VERSION ""

NS_ :

BS_:
BU_: Driving Always Acceories Battery A/C
BO_ 465 First: 8 Driving
   SG_ Accelerator_Position : 47|8@0+ (0.393701,0) [0|100] "%" Driving
   SG_ Brake_Switch : 55|8@0+ (1,0) [0|100] "" Driving

BO_ 674 Power: 8 Always
   SG_ Power_Consumption : 55|16@0+ (0.0004,0) [0|1] "KW" Always
   SG_ Drive_Mode : 31|8@0+ (1,0) [0|1] "" Driving

BO_ 648 Acceories: 8 Acceories
   SG_ Doors : 23|8@0+ (1,0) [0|1] "" Acceories
   SG_ Lights : 15|8@0+ (1,0) [0|1] "" Acceories

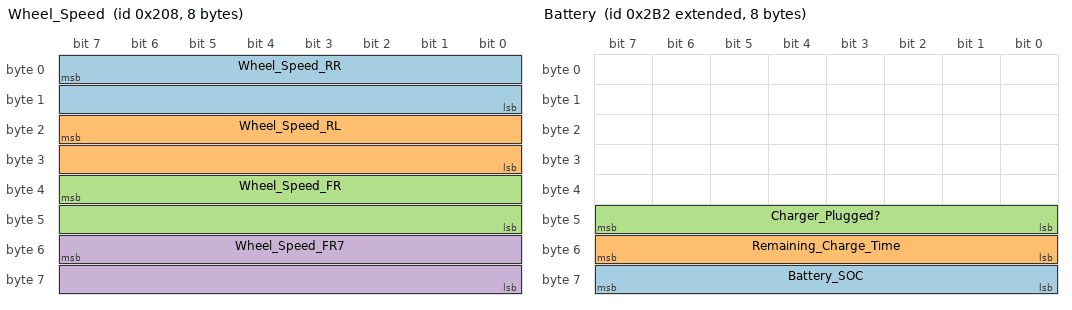
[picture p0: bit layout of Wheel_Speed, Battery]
BO_ 520 Wheel_Speed: 8 Driving
   SG_ Wheel_Speed_RR : 7|16@0+ (0.06,0) [0|1] "Km/h" Driving
   SG_ Wheel_Speed_RL : 23|16@0+ (0.06,0) [0|1] "Km/h" Driving
   SG_ Wheel_Speed_FR : 39|16@0+ (0.06,0) [0|1] "Km/h" Vector__XXX
   SG_ Wheel_Speed_FR7 : 55|16@0+ (0.06,0) [0|1] "Km/h" Driving

BO_ 804 Coolant: 8 Driving
   SG_ Coolant_Temp : 15|8@0+ (0.5556,-17.7778) [0|1] "C°" Vector__XXX

BO_ 616 Gear_Position: 8 Driving
   SG_ Gear_Position : 15|16@0+ (1,0) [0|1] "" Driving

BO_ 658 Drive_Mode: 8 Driving
   SG_ Drive_Mode : 31|8@0+ (1,0) [0|1] "" Driving

BO_ 384 Steering_Angle: 8 Driving
   SG_ Steering_Angle : 7|16@0- (0.1,0) [0|1] "°" Driving

BO_ 952 Battery_Voltage: 8 Battery
   SG_ Battery_Voltage : 7|16@0+ (0.1,0) [0|1] "V" Battery

BO_ 2147484338 Battery: 8 Battery
   SG_ Battery_SOC : 63|8@0+ (0.5,0) [0|100] "%" Battery
   SG_ Remaining_Charge_Time : 55|8@0+ (1,0) [0|100] "min" Battery
   SG_ Charger_Plugged? : 47|8@0+ (1,0) [0|1] "" Battery

CM_ BU_ Driving "On while driving";
CM_ BU_ Always "Always on even while parking";
CM_ BU_ Acceories "Doors and Lights";
BA_DEF_ BO_ "GenMsgBackgroundColor" STRING ;
BA_DEF_ BO_ "GenMsgForegroundColor" STRING ;
BA_DEF_ BO_ "filterlabeling" INT 0 0;
BA_DEF_ BO_ "filterlabeling" INT 0 0;
BA_DEF_ BO_ "filterlabeling" INT 0 0;
BA_DEF_ BO_ "filterlabeling" INT 0 0;
BA_DEF_ BO_ "filterlabeling" INT 0 0;
BA_DEF_ BO_ "filterlabeling" INT 0 0;
BA_DEF_ BO_ "filterlabeling" INT 0 0;
BA_DEF_ BO_ "filterlabeling" INT 0 0;
BA_DEF_ BO_ "filterlabeling" INT 0 0;
BA_DEF_ BO_ "filterlabeling" INT 0 0;
BA_DEF_ BO_ "filterlabeling" INT 0 0;
BA_DEF_DEF_ "GenMsgBackgroundColor" "#ffffff";
BA_DEF_DEF_ "GenMsgForegroundColor" "#000000";
BA_DEF_DEF_ "filterlabeling" 1;
BA_ "GenMsgBackgroundColor" BO_ 465 "#d3d3d3";
BA_ "GenMsgBackgroundColor" BO_ 616 "#dfdfdf";
VAL_ 465 Brake_Switch 64 "On" 0 "Off";
VAL_ 674 Drive_Mode 26 "B+" 17 "B-" 9 "S_B-" 52 "Long_Milage";
VAL_ 648 Doors 128 "FL_Door_Open" 64 "FR_Door_Open" 32 "RL_Door_Open" 16 "RR_Door_Open" 8 "Back_Door_Open" 192 "FL_+_FR_Door_Open" 208 "FL_+_FR_+_RR_Door_Open" 240 "FL_+_FR_+_RL_+_RR_Door_Open" 248 "All_Doors_Open" 184 "FL_+_RR_+_RL_+_Back_Door_Open" 56 "RR_+_RL_+_Back_Door_Open" 40 "RL_+_Back_Door_Open";
VAL_ 648 Lights 64 "Left_Signal_Blink" 16 "Right_Signal_Blink" 80 "Hazard_Blink";
VAL_ 616 Gear_Position 2586 "P" 16 "N" 2843 "D" 283 "S" 2329 "R";
VAL_ 658 Drive_Mode 26 "B+" 17 "B-" 9 "S_B-" 52 "Long_Milage";
VAL_ 2147484338 Charger_Plugged? 32 "Yes" 0 "No" 0 "";
